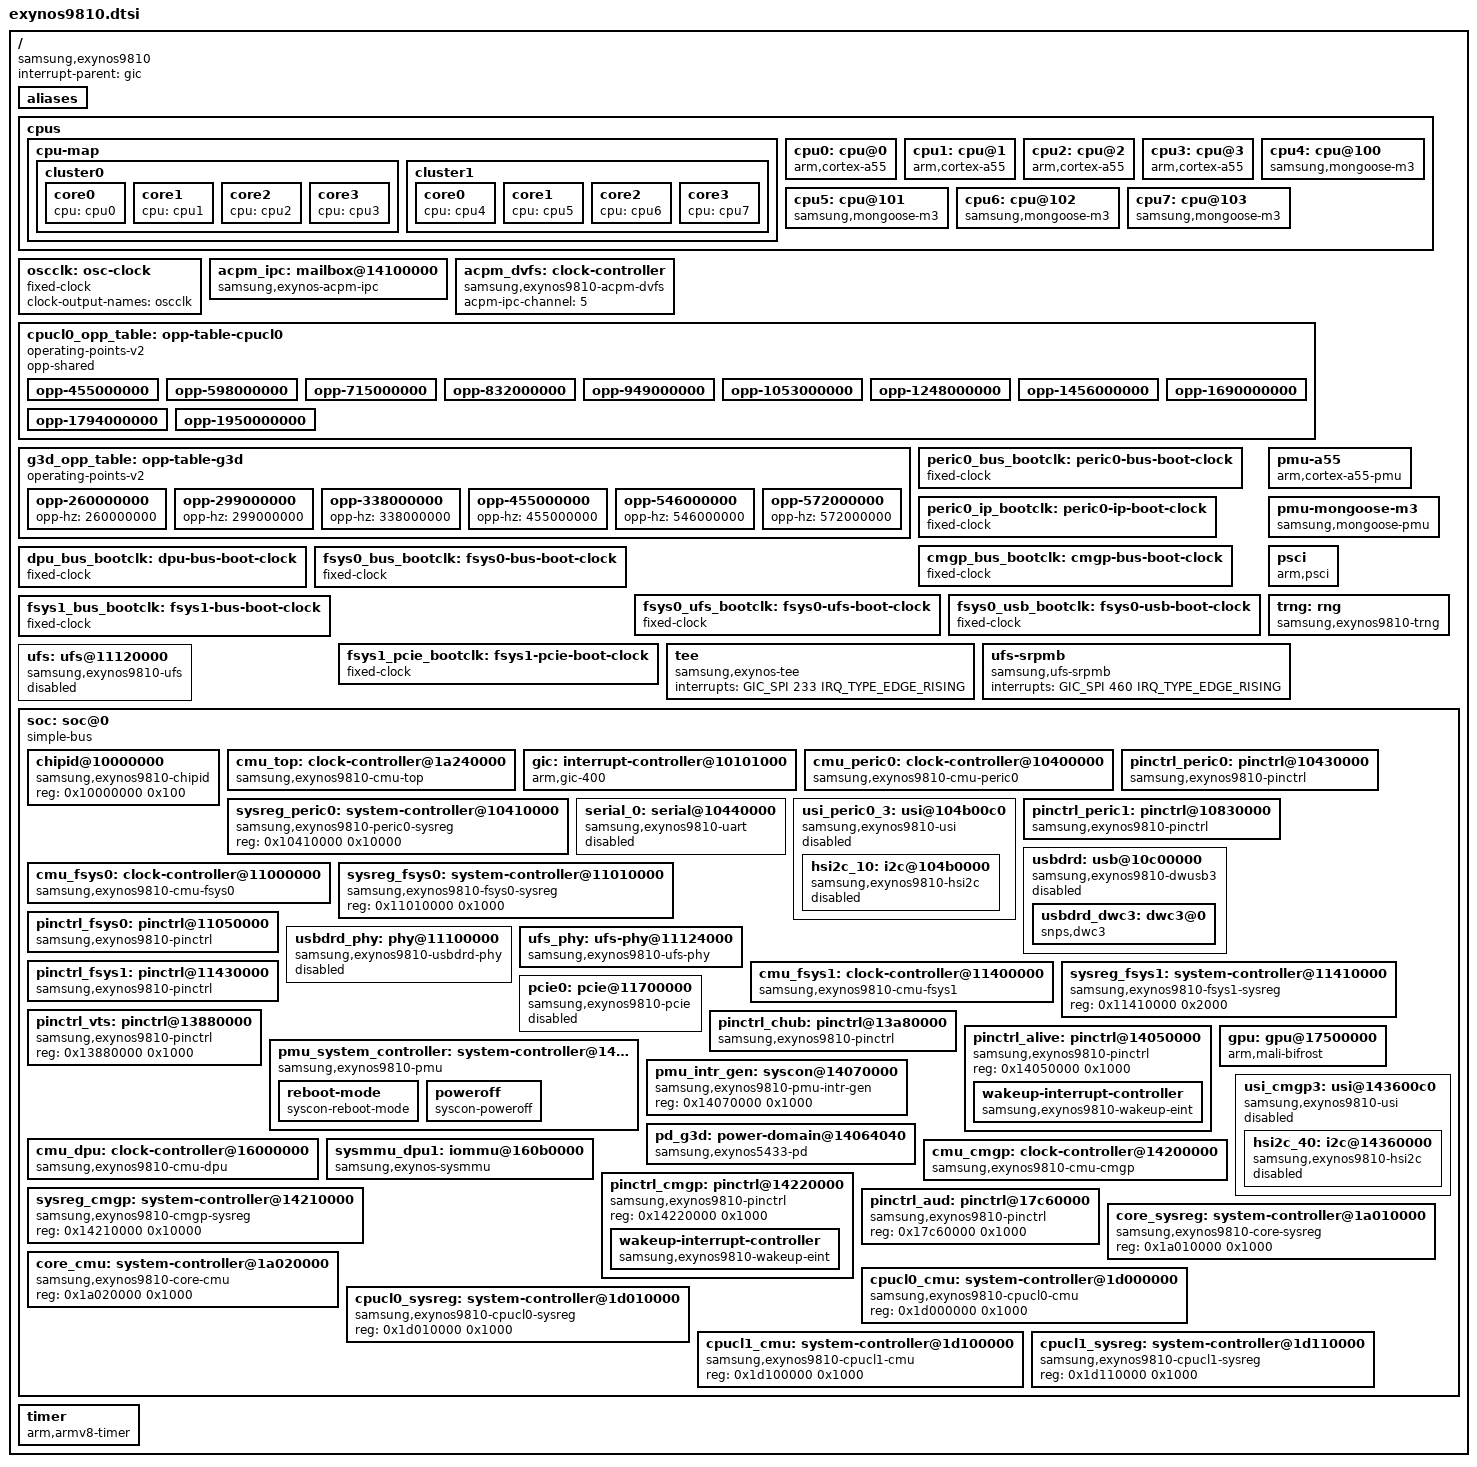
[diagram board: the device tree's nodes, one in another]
// SPDX-License-Identifier: GPL-2.0 OR BSD-3-Clause
/*
 * Samsung Exynos 9810 SoC device tree source
 *
 * Copyright (c) 2024 Markuss Broks <markuss.broks@gmail.com>
 * Copyright (c) 2024 Maksym Holovach <nergzd@nergzd723.xyz>
 */

#include <dt-bindings/interrupt-controller/arm-gic.h>
#include <dt-bindings/clock/samsung,exynos9810.h>
#include <dt-bindings/gpio/gpio.h>
#include <dt-bindings/soc/samsung,exynos-usi.h>

/ {
	compatible = "samsung,exynos9810";
	#address-cells = <2>;
	#size-cells = <1>;

	interrupt-parent = <&gic>;

	aliases {
		pinctrl0 = &pinctrl_alive;
		pinctrl1 = &pinctrl_aud;
		pinctrl2 = &pinctrl_chub;
		pinctrl3 = &pinctrl_cmgp;
		pinctrl4 = &pinctrl_fsys0;
		pinctrl5 = &pinctrl_fsys1;
		pinctrl6 = &pinctrl_peric0;
		pinctrl7 = &pinctrl_peric1;
		pinctrl8 = &pinctrl_vts;
		serial0 = &serial_0;
	};

	cpus {
		#address-cells = <1>;
		#size-cells = <0>;

		cpu-map {
			cluster0 {
				core0 {
					cpu = <&cpu0>;
				};
				core1 {
					cpu = <&cpu1>;
				};
				core2 {
					cpu = <&cpu2>;
				};
				core3 {
					cpu = <&cpu3>;
				};
			};

			cluster1 {
				core0 {
					cpu = <&cpu4>;
				};
				core1 {
					cpu = <&cpu5>;
				};
				core2 {
					cpu = <&cpu6>;
				};
				core3 {
					cpu = <&cpu7>;
				};
			};
		};

		cpu0: cpu@0 {
			device_type = "cpu";
			compatible = "arm,cortex-a55";
			reg = <0x0>;
			enable-method = "psci";
			clocks = <&acpm_dvfs CLK_ACPM_DVFS_CPUCL0>;
			operating-points-v2 = <&cpucl0_opp_table>;
		};

		cpu1: cpu@1 {
			device_type = "cpu";
			compatible = "arm,cortex-a55";
			reg = <0x1>;
			enable-method = "psci";
			clocks = <&acpm_dvfs CLK_ACPM_DVFS_CPUCL0>;
			operating-points-v2 = <&cpucl0_opp_table>;
		};

		cpu2: cpu@2 {
			device_type = "cpu";
			compatible = "arm,cortex-a55";
			reg = <0x2>;
			enable-method = "psci";
			clocks = <&acpm_dvfs CLK_ACPM_DVFS_CPUCL0>;
			operating-points-v2 = <&cpucl0_opp_table>;
		};

		cpu3: cpu@3 {
			device_type = "cpu";
			compatible = "arm,cortex-a55";
			reg = <0x3>;
			enable-method = "psci";
			clocks = <&acpm_dvfs CLK_ACPM_DVFS_CPUCL0>;
			operating-points-v2 = <&cpucl0_opp_table>;
		};

		cpu4: cpu@100 {
			device_type = "cpu";
			compatible = "samsung,mongoose-m3";
			reg = <0x100>;
			enable-method = "psci";
		};

		cpu5: cpu@101 {
			device_type = "cpu";
			compatible = "samsung,mongoose-m3";
			reg = <0x101>;
			enable-method = "psci";
		};

		cpu6: cpu@102 {
			device_type = "cpu";
			compatible = "samsung,mongoose-m3";
			reg = <0x102>;
			enable-method = "psci";
		};

		cpu7: cpu@103 {
			device_type = "cpu";
			compatible = "samsung,mongoose-m3";
			reg = <0x103>;
			enable-method = "psci";
		};
	};

	oscclk: osc-clock {
		compatible = "fixed-clock";
		#clock-cells = <0>;
		clock-output-names = "oscclk";
	};

	acpm_ipc: mailbox@14100000 {
		compatible = "samsung,exynos-acpm-ipc";
		reg = <0x0 0x14100000 0x1000>,
		      <0x0 0x02039000 0x30000>;
		reg-names = "mailbox", "sram";
		interrupts = <GIC_SPI 68 IRQ_TYPE_LEVEL_HIGH>;
		initdata-base = <0x7f00>;
		num-timestamps = <32>;
		debug-log-level = <0>;
		logging-period = <0>;
		samsung,plugin-channel = <4>;
		samsung,dvfs-channel = <5>;
	};

	acpm_dvfs: clock-controller {
		compatible = "samsung,exynos9810-acpm-dvfs";
		#clock-cells = <1>;
		acpm-ipc-channel = <5>;
	};

	cpucl0_opp_table: opp-table-cpucl0 {
		compatible = "operating-points-v2";
		opp-shared;

		opp-455000000 {
			opp-hz = /bits/ 64 <455000000>;
			clock-latency-ns = <100000>;
		};

		opp-598000000 {
			opp-hz = /bits/ 64 <598000000>;
			clock-latency-ns = <100000>;
		};

		opp-715000000 {
			opp-hz = /bits/ 64 <715000000>;
			clock-latency-ns = <100000>;
		};

		opp-832000000 {
			opp-hz = /bits/ 64 <832000000>;
			clock-latency-ns = <100000>;
		};

		opp-949000000 {
			opp-hz = /bits/ 64 <949000000>;
			clock-latency-ns = <100000>;
		};

		opp-1053000000 {
			opp-hz = /bits/ 64 <1053000000>;
			clock-latency-ns = <100000>;
		};

		opp-1248000000 {
			opp-hz = /bits/ 64 <1248000000>;
			clock-latency-ns = <100000>;
		};

		opp-1456000000 {
			opp-hz = /bits/ 64 <1456000000>;
			clock-latency-ns = <100000>;
		};

		opp-1690000000 {
			opp-hz = /bits/ 64 <1690000000>;
			clock-latency-ns = <100000>;
		};

		opp-1794000000 {
			opp-hz = /bits/ 64 <1794000000>;
			clock-latency-ns = <100000>;
		};

		opp-1950000000 {
			opp-hz = /bits/ 64 <1950000000>;
			clock-latency-ns = <100000>;
		};
	};

	g3d_opp_table: opp-table-g3d {
		compatible = "operating-points-v2";

		opp-260000000 {
			opp-hz = /bits/ 64 <260000000>;
		};

		opp-299000000 {
			opp-hz = /bits/ 64 <299000000>;
		};

		opp-338000000 {
			opp-hz = /bits/ 64 <338000000>;
		};

		opp-455000000 {
			opp-hz = /bits/ 64 <455000000>;
		};

		opp-546000000 {
			opp-hz = /bits/ 64 <546000000>;
		};

		opp-572000000 {
			opp-hz = /bits/ 64 <572000000>;
		};
	};

	/*
	 * Most of CMU_TOP is not implemented yet. S-Boot leaves these domain
	 * inputs running at the rates below, so describe the preserved mux and
	 * divider outputs as bootstrap clocks until the complete tree is
	 * available.
	 */
	peric0_bus_bootclk: peric0-bus-boot-clock {
		compatible = "fixed-clock";
		#clock-cells = <0>;
		clock-frequency = <200000000>;
		clock-output-names = "dout_clkcmu_peric0_bus";
	};

	peric0_ip_bootclk: peric0-ip-boot-clock {
		compatible = "fixed-clock";
		#clock-cells = <0>;
		clock-frequency = <400000000>;
		clock-output-names = "dout_clkcmu_peric0_ip";
	};

	cmgp_bus_bootclk: cmgp-bus-boot-clock {
		compatible = "fixed-clock";
		#clock-cells = <0>;
		clock-frequency = <200000000>;
		clock-output-names = "cmgp_bus_bootclk";
	};

	dpu_bus_bootclk: dpu-bus-boot-clock {
		compatible = "fixed-clock";
		#clock-cells = <0>;
		/*
		 * Bootstrap metadata for the bus rate preserved by the
		 * bootloader. Complete CMU_TOP modelling will replace this.
		 */
		clock-frequency = <400000000>;
		clock-output-names = "dpu_bus_bootclk";
	};

	fsys0_bus_bootclk: fsys0-bus-boot-clock {
		compatible = "fixed-clock";
		#clock-cells = <0>;
		clock-frequency = <177666666>;
		clock-output-names = "dout_clkcmu_fsys0_bus";
	};

	fsys0_ufs_bootclk: fsys0-ufs-boot-clock {
		compatible = "fixed-clock";
		#clock-cells = <0>;
		clock-frequency = <177666666>;
		clock-output-names = "dout_clkcmu_fsys0_ufs_embd";
	};

	fsys0_usb_bootclk: fsys0-usb-boot-clock {
		compatible = "fixed-clock";
		#clock-cells = <0>;
		clock-frequency = <266500000>;
		clock-output-names = "dout_clkcmu_fsys0_usb30drd";
	};

	fsys1_bus_bootclk: fsys1-bus-boot-clock {
		compatible = "fixed-clock";
		#clock-cells = <0>;
		clock-frequency = <200000000>;
		clock-output-names = "dout_clkcmu_fsys1_bus";
	};

	fsys1_pcie_bootclk: fsys1-pcie-boot-clock {
		compatible = "fixed-clock";
		#clock-cells = <0>;
		clock-frequency = <26000000>;
		clock-output-names = "dout_clkcmu_fsys1_pcie";
	};

	pmu-a55 {
		compatible = "arm,cortex-a55-pmu";
		interrupts = <GIC_SPI 144 IRQ_TYPE_LEVEL_HIGH>,
			     <GIC_SPI 145 IRQ_TYPE_LEVEL_HIGH>,
			     <GIC_SPI 146 IRQ_TYPE_LEVEL_HIGH>,
			     <GIC_SPI 147 IRQ_TYPE_LEVEL_HIGH>;
		interrupt-affinity = <&cpu0>,
				     <&cpu1>,
				     <&cpu2>,
				     <&cpu3>;
	};

	pmu-mongoose-m3 {
		compatible = "samsung,mongoose-pmu";
		interrupts = <GIC_SPI 167 IRQ_TYPE_LEVEL_HIGH>,
			     <GIC_SPI 168 IRQ_TYPE_LEVEL_HIGH>,
			     <GIC_SPI 169 IRQ_TYPE_LEVEL_HIGH>,
			     <GIC_SPI 170 IRQ_TYPE_LEVEL_HIGH>;
		interrupt-affinity = <&cpu4>,
				     <&cpu5>,
				     <&cpu6>,
				     <&cpu7>;
	};

	psci {
		compatible = "arm,psci";
		method = "smc";
		cpu_off = <0x84000002>;
		cpu_on = <0xc4000003>;
		cpu_suspend = <0xc4000001>;
	};

	tee {
		compatible = "samsung,exynos-tee";
		interrupts = <GIC_SPI 233 IRQ_TYPE_EDGE_RISING>;
	};

	trng: rng {
		compatible = "samsung,exynos9810-trng";
	};

	ufs-srpmb {
		compatible = "samsung,ufs-srpmb";
		interrupts = <GIC_SPI 460 IRQ_TYPE_EDGE_RISING>;
	};

	ufs: ufs@11120000 {
		compatible = "samsung,exynos9810-ufs";
		reg = <0x0 0x11120000 0x200>,
		      <0x0 0x11121100 0x200>,
		      <0x0 0x11110000 0x8000>,
		      <0x0 0x11130000 0x100>;
		reg-names = "hci", "vs_hci", "unipro", "ufsp";
		interrupts = <GIC_SPI 242 IRQ_TYPE_LEVEL_HIGH>;
		clocks = <&cmu_fsys0 CLK_GOUT_FSYS0_UFS_EMBD_ACLK>,
			 <&cmu_fsys0 CLK_GOUT_FSYS0_UFS_EMBD_UNIPRO>;
		clock-names = "core_clk", "sclk_unipro_main";
		freq-table-hz = <0 0>, <0 0>;
		dma-coherent;
		phys = <&ufs_phy>;
		phy-names = "ufs-phy";
		pinctrl-0 = <&ufs_rst_n &ufs_refclk_out>;
		pinctrl-names = "default";
		samsung,sysreg = <&sysreg_fsys0 0x700>;
		status = "disabled";
	};

	soc: soc@0 {
		compatible = "simple-bus";
		ranges = <0x0 0x0 0x0 0x20000000>;

		#address-cells = <1>;
		#size-cells = <1>;

		chipid@10000000 {
			compatible = "samsung,exynos9810-chipid",
				     "samsung,exynos850-chipid";
			reg = <0x10000000 0x100>;
		};

		cmu_top: clock-controller@1a240000 {
			compatible = "samsung,exynos9810-cmu-top";
			reg = <0x1a240000 0x8000>;
			#clock-cells = <1>;

			clocks = <&oscclk>, <&cmgp_bus_bootclk>;
			clock-names = "oscclk", "cmgp_bus_bootclk";
		};

		gic: interrupt-controller@10101000 {
			compatible = "arm,gic-400";
			reg = <0x10101000 0x1000>,
			      <0x10102000 0x1000>,
			      <0x10104000 0x2000>,
			      <0x10106000 0x2000>;
			#interrupt-cells = <3>;
			interrupt-controller;
			interrupts = <GIC_PPI 9 (GIC_CPU_MASK_SIMPLE(8) |
						 IRQ_TYPE_LEVEL_HIGH)>;
			#address-cells = <0>;
			#size-cells = <1>;
		};

		cmu_peric0: clock-controller@10400000 {
			compatible = "samsung,exynos9810-cmu-peric0";
			reg = <0x10400000 0x8000>;
			#clock-cells = <1>;

			clocks = <&oscclk>, <&peric0_bus_bootclk>,
				 <&peric0_ip_bootclk>;
			clock-names = "oscclk", "dout_clkcmu_peric0_bus",
				      "dout_clkcmu_peric0_ip";
		};

		sysreg_peric0: system-controller@10410000 {
			compatible = "samsung,exynos9810-peric0-sysreg", "syscon";
			reg = <0x10410000 0x10000>;
		};

		pinctrl_peric0: pinctrl@10430000 {
			compatible = "samsung,exynos9810-pinctrl";
			reg = <0x10430000 0x1000>;
			interrupts = <GIC_SPI 396 IRQ_TYPE_LEVEL_HIGH>;
		};

		serial_0: serial@10440000 {
			compatible = "samsung,exynos9810-uart",
				     "samsung,exynos8895-uart";
			reg = <0x10440000 0x100>;
			interrupts = <GIC_SPI 397 IRQ_TYPE_LEVEL_HIGH>;
			clocks = <&cmu_peric0 CLK_GOUT_PERIC0_UART_DBG_PCLK>,
				 <&cmu_peric0 CLK_GOUT_PERIC0_UART_DBG_IPCLK>;
			clock-names = "uart", "clk_uart_baud0";
			pinctrl-0 = <&uart0_bus>;
			pinctrl-names = "default";
			samsung,uart-fifosize = <256>;
			status = "disabled";
		};

		usi_peric0_3: usi@104b00c0 {
			compatible = "samsung,exynos9810-usi",
				     "samsung,exynos850-usi";
			reg = <0x104b00c0 0x20>;
			samsung,sysreg = <&sysreg_peric0 0x101c>;
			samsung,mode = <USI_MODE_I2C>;
			#address-cells = <1>;
			#size-cells = <1>;
			ranges;
			clocks = <&cmu_peric0 CLK_GOUT_PERIC0_USI3_PCLK>,
				 <&cmu_peric0 CLK_GOUT_PERIC0_USI3_IPCLK>;
			clock-names = "pclk", "ipclk";
			status = "disabled";

			hsi2c_10: i2c@104b0000 {
				compatible = "samsung,exynos9810-hsi2c";
				reg = <0x104b0000 0xc0>;
				interrupts = <GIC_SPI 404 IRQ_TYPE_LEVEL_HIGH>;
				#address-cells = <1>;
				#size-cells = <0>;
				clock-frequency = <400000>;
				clocks = <&cmu_peric0 CLK_GOUT_PERIC0_USI3_IPCLK>,
					 <&cmu_peric0 CLK_GOUT_PERIC0_USI3_PCLK>;
				clock-names = "hsi2c", "hsi2c_pclk";
				assigned-clocks = <&cmu_peric0 CLK_DOUT_PERIC0_USI3>;
				assigned-clock-rates = <200000000>;
				pinctrl-0 = <&hsi2c10_bus>;
				pinctrl-names = "default";
				status = "disabled";
			};
		};

		pinctrl_peric1: pinctrl@10830000 {
			compatible = "samsung,exynos9810-pinctrl";
			reg = <0x10830000 0x1000>;
			interrupts = <GIC_SPI 421 IRQ_TYPE_LEVEL_HIGH>;
		};

		usbdrd: usb@10c00000 {
			compatible = "samsung,exynos9810-dwusb3";
			reg = <0x10c00000 0x10000>;
			clocks = <&cmu_fsys0 CLK_GOUT_FSYS0_USB30DRD_LINK>,
				 <&cmu_fsys0 CLK_GOUT_FSYS0_USB30DRD_REF>,
				 <&cmu_fsys0 CLK_GOUT_FSYS0_USB30DRD_CTRL>;
			clock-names = "aclk", "sclk", "ctrl";
			#address-cells = <1>;
			#size-cells = <1>;
			ranges = <0x0 0x10c00000 0x10000>;
			status = "disabled";

			usbdrd_dwc3: dwc3@0 {
				compatible = "snps,dwc3";
				reg = <0x0 0x10000>;
				interrupts = <GIC_SPI 244 IRQ_TYPE_LEVEL_HIGH>;
				dr_mode = "peripheral";
				maximum-speed = "high-speed";
				phys = <&usbdrd_phy 0>;
				phy-names = "usb2-phy";
				snps,dis-u2-freeclk-exists-quirk;
				snps,incr-burst-type-adjustment = <1>, <16>;
				snps,quirk-frame-length-adjustment = <0x20>;
				snps,ref-clock-period-ns = <20>;
			};
		};

		cmu_fsys0: clock-controller@11000000 {
			compatible = "samsung,exynos9810-cmu-fsys0";
			reg = <0x11000000 0x8000>;
			#clock-cells = <1>;

			clocks = <&oscclk>, <&fsys0_bus_bootclk>,
				 <&fsys0_ufs_bootclk>, <&fsys0_usb_bootclk>;
			clock-names = "oscclk", "dout_clkcmu_fsys0_bus",
				      "dout_clkcmu_fsys0_ufs_embd",
				      "dout_clkcmu_fsys0_usb30drd";
		};

		sysreg_fsys0: system-controller@11010000 {
			compatible = "samsung,exynos9810-fsys0-sysreg", "syscon";
			reg = <0x11010000 0x1000>;
		};

		pinctrl_fsys0: pinctrl@11050000 {
			compatible = "samsung,exynos9810-pinctrl";
			reg = <0x11050000 0x1000>;
			interrupts = <GIC_SPI 243 IRQ_TYPE_LEVEL_HIGH>;
		};

		usbdrd_phy: phy@11100000 {
			compatible = "samsung,exynos9810-usbdrd-phy";
			reg = <0x11100000 0x200>;
			clocks = <&cmu_fsys0 CLK_GOUT_FSYS0_USB30DRD_LINK>,
				 <&oscclk>;
			clock-names = "phy", "ref";
			samsung,pmu-syscon = <&pmu_system_controller>;
			#phy-cells = <1>;
			status = "disabled";
		};

		ufs_phy: ufs-phy@11124000 {
			compatible = "samsung,exynos9810-ufs-phy";
			reg = <0x11124000 0x800>;
			reg-names = "phy-pma";
			clocks = <&oscclk>;
			clock-names = "ref_clk";
			#phy-cells = <0>;
			samsung,pmu-syscon = <&pmu_system_controller 0x724>;
		};

		cmu_fsys1: clock-controller@11400000 {
			compatible = "samsung,exynos9810-cmu-fsys1";
			reg = <0x11400000 0x8000>;
			#clock-cells = <1>;

			clocks = <&oscclk>, <&fsys1_bus_bootclk>,
				 <&fsys1_pcie_bootclk>;
			clock-names = "oscclk", "dout_clkcmu_fsys1_bus",
				      "dout_clkcmu_fsys1_pcie";
		};

		sysreg_fsys1: system-controller@11410000 {
			compatible = "samsung,exynos9810-fsys1-sysreg", "syscon";
			reg = <0x11410000 0x2000>;
		};

		pinctrl_fsys1: pinctrl@11430000 {
			compatible = "samsung,exynos9810-pinctrl";
			reg = <0x11430000 0x1000>;
			interrupts = <GIC_SPI 250 IRQ_TYPE_LEVEL_HIGH>;
		};

		pcie0: pcie@11700000 {
			compatible = "samsung,exynos9810-pcie";
			reg = <0x11700000 0x1000>,
			      <0x116a0000 0x1000>,
			      <0x12800000 0x2000>,
			      <0x116c0000 0x2000>;
			reg-names = "dbi", "elbi", "config", "phy";
			interrupts = <GIC_SPI 253 IRQ_TYPE_LEVEL_HIGH>;

			clocks = <&cmu_fsys1 CLK_GOUT_FSYS1_PCIE_PHY_REF>,
				 <&cmu_fsys1 CLK_GOUT_FSYS1_PCIE_DBI>,
				 <&cmu_fsys1 CLK_GOUT_FSYS1_PCIE_PHY_APB>,
				 <&cmu_fsys1 CLK_GOUT_FSYS1_PCIE_MSTR>,
				 <&cmu_fsys1 CLK_GOUT_FSYS1_PCIE_SUBCTRL>,
				 <&cmu_fsys1 CLK_GOUT_FSYS1_PCIE_PCS>,
				 <&cmu_fsys1 CLK_GOUT_FSYS1_PCIE_SLV>;
			clock-names = "phy_ref", "dbi", "phy_apb", "mstr",
				      "subctrl", "pcs", "slv";

			#address-cells = <3>;
			#size-cells = <2>;
			#interrupt-cells = <1>;
			device_type = "pci";
			bus-range = <0x00 0xff>;
			ranges = <0x82000000 0 0x11800000
				  0x11800000 0 0x00ff0000>;
			interrupt-map-mask = <0 0 0 0>;
			interrupt-map = <0 0 0 0 &gic GIC_SPI 253
					 IRQ_TYPE_LEVEL_HIGH>;

			num-lanes = <1>;
			num-viewport = <3>;
			max-link-speed = <2>;
			reset-gpios = <&gpf2 2 GPIO_ACTIVE_LOW>;
			pinctrl-0 = <&pcie0_clkreq &pcie0_perst>;
			pinctrl-names = "default";
			samsung,fsys-sysreg = <&sysreg_fsys1>;
			samsung,pmu-syscon = <&pmu_system_controller>;
			dma-coherent;
			status = "disabled";
		};

		pinctrl_vts: pinctrl@13880000 {
			compatible = "samsung,exynos9810-pinctrl";
			reg = <0x13880000 0x1000>;
		};

		pinctrl_chub: pinctrl@13a80000 {
			compatible = "samsung,exynos9810-pinctrl";
			reg = <0x13a80000 0x1000>;
			interrupts = <GIC_SPI 109 IRQ_TYPE_LEVEL_HIGH>;
		};

		pinctrl_alive: pinctrl@14050000 {
			compatible = "samsung,exynos9810-pinctrl";
			reg = <0x14050000 0x1000>;

			wakeup-interrupt-controller {
				compatible = "samsung,exynos9810-wakeup-eint",
					     "samsung,exynos850-wakeup-eint",
					     "samsung,exynos7-wakeup-eint";
			};
		};

		pmu_system_controller: system-controller@14060000 {
			compatible = "samsung,exynos9810-pmu",
				     "samsung,exynos7-pmu", "syscon";
			reg = <0x14060000 0x10000>;
			samsung,core-cmu-syscon = <&core_cmu>;
			samsung,core-sysreg-syscon = <&core_sysreg>;
			samsung,cpucl0-cmu-syscon = <&cpucl0_cmu>;
			samsung,cpucl0-sysreg-syscon = <&cpucl0_sysreg>;
			samsung,cpucl1-cmu-syscon = <&cpucl1_cmu>;
			samsung,cpucl1-sysreg-syscon = <&cpucl1_sysreg>;
			samsung,pmu-intr-gen-syscon = <&pmu_intr_gen>;

			reboot-mode {
				compatible = "syscon-reboot-mode";
				offset = <0x080c>;
				mode-normal = <0x12345670>;
				/* Android user-requested system reboot reasons. */
				mode-userrequested = <0x12345670>;
				mode-userrequested-recovery = <0x12345670>;
				mode-download = <0x12345671>;
				mode-recovery = <0x12345674>;
				mode-bootloader = <0x1234567d>;
			};

			poweroff {
				compatible = "syscon-poweroff";
				offset = <0x330c>;
				mask = <0x100>;
				value = <0x0>;
			};
		};

		pmu_intr_gen: syscon@14070000 {
			compatible = "samsung,exynos9810-pmu-intr-gen", "syscon";
			reg = <0x14070000 0x1000>;
		};

		pd_g3d: power-domain@14064040 {
			compatible = "samsung,exynos5433-pd";
			reg = <0x14064040 0x20>;
			#power-domain-cells = <0>;
			label = "G3D";
		};

		gpu: gpu@17500000 {
			compatible = "arm,mali-bifrost";
			reg = <0x17500000 0x5000>;
			interrupts = <GIC_SPI 282 IRQ_TYPE_LEVEL_HIGH>,
				     <GIC_SPI 281 IRQ_TYPE_LEVEL_HIGH>,
				     <GIC_SPI 283 IRQ_TYPE_LEVEL_HIGH>;
			interrupt-names = "JOB", "MMU", "GPU";
			clocks = <&acpm_dvfs CLK_ACPM_DVFS_G3D>;
			clock-names = "core";
			power-domains = <&pd_g3d>;
			operating-points-v2 = <&g3d_opp_table>;
			#cooling-cells = <2>;
		};

		cmu_dpu: clock-controller@16000000 {
			compatible = "samsung,exynos9810-cmu-dpu";
			reg = <0x16000000 0x8000>;
			#clock-cells = <1>;

			clocks = <&oscclk>,
				 <&cmu_top CLK_GOUT_TOP_DPU_BUS>;
			clock-names = "oscclk", "dout_clkcmu_dpu_bus";
		};

		sysmmu_dpu1: iommu@160b0000 {
			compatible = "samsung,exynos-sysmmu";
			reg = <0x160b0000 0x9000>;
			interrupts = <GIC_SPI 213 IRQ_TYPE_LEVEL_HIGH>;
			clocks =
				<&cmu_dpu CLK_GOUT_DPU_SYSMMU_DPUD1_QCH>,
				<&cmu_dpu CLK_GOUT_DPU_SYSMMU_DPUD1_PCLK>;
			clock-names = "aclk", "pclk";
			#iommu-cells = <0>;
		};

		cmu_cmgp: clock-controller@14200000 {
			compatible = "samsung,exynos9810-cmu-cmgp";
			reg = <0x14200000 0x8000>;
			#clock-cells = <1>;

			clocks = <&oscclk>,
				 <&cmu_top CLK_GOUT_TOP_CMGP_BUS>;
			clock-names = "oscclk", "dout_clkcmu_cmgp_bus";
		};

		sysreg_cmgp: system-controller@14210000 {
			compatible = "samsung,exynos9810-cmgp-sysreg", "syscon";
			reg = <0x14210000 0x10000>;
		};

		pinctrl_cmgp: pinctrl@14220000 {
			compatible = "samsung,exynos9810-pinctrl";
			reg = <0x14220000 0x1000>;

			wakeup-interrupt-controller {
				compatible = "samsung,exynos9810-wakeup-eint",
					     "samsung,exynos850-wakeup-eint",
					     "samsung,exynos7-wakeup-eint";
			};
		};

		usi_cmgp3: usi@143600c0 {
			compatible = "samsung,exynos9810-usi",
				     "samsung,exynos850-usi";
			reg = <0x143600c0 0x20>;
			samsung,sysreg = <&sysreg_cmgp 0x2030>;
			samsung,mode = <USI_MODE_I2C>;
			#address-cells = <1>;
			#size-cells = <1>;
			ranges;
			clocks = <&cmu_cmgp CLK_GOUT_CMGP_USI3_PCLK>,
				 <&cmu_cmgp CLK_GOUT_CMGP_USI3_IPCLK>;
			clock-names = "pclk", "ipclk";
			status = "disabled";

			hsi2c_40: i2c@14360000 {
				compatible = "samsung,exynos9810-hsi2c";
				reg = <0x14360000 0xc0>;
				interrupts = <GIC_SPI 6 IRQ_TYPE_LEVEL_HIGH>;
				#address-cells = <1>;
				#size-cells = <0>;
				clock-frequency = <400000>;
				clocks = <&cmu_cmgp CLK_GOUT_CMGP_USI3_IPCLK>,
					 <&cmu_cmgp CLK_GOUT_CMGP_USI3_PCLK>;
				clock-names = "hsi2c", "hsi2c_pclk";
				pinctrl-0 = <&hsi2c40_bus>;
				pinctrl-names = "default";
				status = "disabled";
			};
		};

		pinctrl_aud: pinctrl@17c60000 {
			compatible = "samsung,exynos9810-pinctrl";
			reg = <0x17c60000 0x1000>;
		};

		core_sysreg: system-controller@1a010000 {
			compatible = "samsung,exynos9810-core-sysreg", "syscon";
			reg = <0x1a010000 0x1000>;
		};

		core_cmu: system-controller@1a020000 {
			compatible = "samsung,exynos9810-core-cmu", "syscon";
			reg = <0x1a020000 0x1000>;
		};

		cpucl0_cmu: system-controller@1d000000 {
			compatible = "samsung,exynos9810-cpucl0-cmu", "syscon";
			reg = <0x1d000000 0x1000>;
		};

		cpucl0_sysreg: system-controller@1d010000 {
			compatible = "samsung,exynos9810-cpucl0-sysreg", "syscon";
			reg = <0x1d010000 0x1000>;
		};

		cpucl1_cmu: system-controller@1d100000 {
			compatible = "samsung,exynos9810-cpucl1-cmu", "syscon";
			reg = <0x1d100000 0x1000>;
		};

		cpucl1_sysreg: system-controller@1d110000 {
			compatible = "samsung,exynos9810-cpucl1-sysreg", "syscon";
			reg = <0x1d110000 0x1000>;
		};
	};

	timer {
		compatible = "arm,armv8-timer";
		/* Hypervisor Virtual Timer interrupt is not wired to GIC */
		interrupts = <GIC_PPI 13 (GIC_CPU_MASK_SIMPLE(8) | IRQ_TYPE_LEVEL_LOW)>,
			     <GIC_PPI 14 (GIC_CPU_MASK_SIMPLE(8) | IRQ_TYPE_LEVEL_LOW)>,
			     <GIC_PPI 11 (GIC_CPU_MASK_SIMPLE(8) | IRQ_TYPE_LEVEL_LOW)>,
			     <GIC_PPI 10 (GIC_CPU_MASK_SIMPLE(8) | IRQ_TYPE_LEVEL_LOW)>;
		/*
		 * Non-updatable, broken stock Samsung bootloader does not
		 * configure CNTFRQ_EL0
		 */
		clock-frequency = <26000000>;
	};
};

#include "exynos9810-pinctrl.dtsi"
#include "arm/samsung/exynos-syscon-restart.dtsi"
